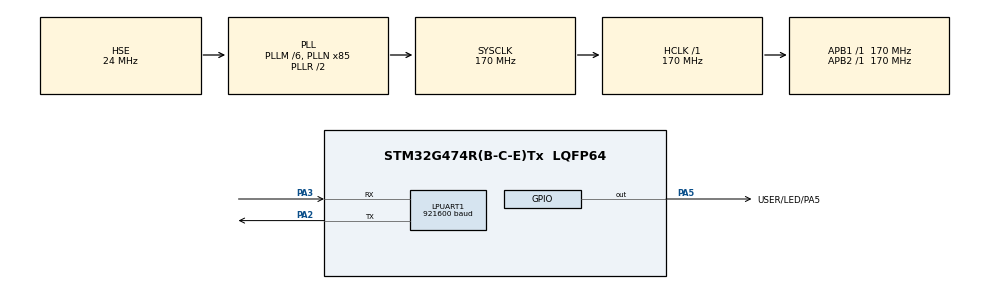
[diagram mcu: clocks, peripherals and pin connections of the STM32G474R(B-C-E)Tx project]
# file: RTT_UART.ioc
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LPUART1.BaudRate=921600
LPUART1.RXFIFOThreshold=UART_RXFIFO_THRESHOLD_3_4
LPUART1.TXFIFOThreshold=UART_TXFIFO_THRESHOLD_3_4
Mcu.Family=STM32G4
Mcu.Name=STM32G474R(B-C-E)Tx
Mcu.Package=LQFP64
NVIC.LPUART1_IRQn=true\:0\:0\:false\:false\:true\:true\:true
NVIC.PriorityGroup=NVIC_PRIORITYGROUP_4
PA2.Mode=Asynchronous
PA2.Signal=LPUART1_TX
PA3.Mode=Asynchronous
PA3.Signal=LPUART1_RX
PA5.GPIO_Label=USER/LED/PA5
PA5.Signal=GPIO_Output
PC14-OSC32_IN.Mode=LSE-External-Oscillator
PC14-OSC32_IN.Signal=RCC_OSC32_IN
PC15-OSC32_OUT.Mode=LSE-External-Oscillator
PC15-OSC32_OUT.Signal=RCC_OSC32_OUT
PF0-OSC_IN.Mode=HSE-External-Oscillator
PF0-OSC_IN.Signal=RCC_OSC_IN
PF1-OSC_OUT.Mode=HSE-External-Oscillator
PF1-OSC_OUT.Signal=RCC_OSC_OUT
ProjectManager.HeapSize=0x200
ProjectManager.StackSize=0x400
ProjectManager.TargetToolchain=MDK-ARM V5.27
RCC.ADC12Freq_Value=170000000
RCC.ADC345Freq_Value=170000000
RCC.AHBFreq_Value=170000000
RCC.APB1Freq_Value=170000000
RCC.APB1TimFreq_Value=170000000
RCC.APB2Freq_Value=170000000
RCC.APB2TimFreq_Value=170000000
RCC.CortexFreq_Value=170000000
RCC.EXTERNAL_CLOCK_VALUE=12288000
RCC.HCLKFreq_Value=170000000
RCC.HSE_VALUE=24000000
RCC.HSI48_VALUE=48000000
RCC.HSI_VALUE=16000000
RCC.PLLM=RCC_PLLM_DIV6
RCC.PLLN=85
RCC.PLLSourceVirtual=RCC_PLLSOURCE_HSE
RCC.SYSCLKFreq_VALUE=170000000
RCC.SYSCLKSource=RCC_SYSCLKSOURCE_PLLCLK
RCC.USBFreq_Value=170000000
RCC.VCOOutputFreq_Value=340000000
RealThread.RT-Thread.3.1.3.RTAaThreadCcRTOSJjkernel=true
RealThread.RT-Thread.3.1.3.RTAaThreadCcRTOSJjshell=true
VP_RealThread.RT-Thread_VS_RTOSJjRTAaThread_3.1.3.Mode=RTOSJjRTAaThread
VP_SYS_VS_DBSignals.Mode=DisableDeadBatterySignals
board=custom

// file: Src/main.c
/* USER CODE BEGIN Header */
/**
  ******************************************************************************
  * @file           : main.c
  * @brief          : Main program body
  ******************************************************************************
  * @attention
  *
  * <h2><center>&copy; Copyright (c) 2020 STMicroelectronics.
  * All rights reserved.</center></h2>
  *
  * This software component is licensed by ST under Ultimate Liberty license
  * SLA0044, the "License"; You may not use this file except in compliance with
  * the License. You may obtain a copy of the License at:
  *                             www.st.com/SLA0044
  *
  ******************************************************************************
  */
/* USER CODE END Header */

#include "main.h"
#include "usart.h"
#include "gpio.h"
//#include <stdio.h>
/* USER CODE BEGIN Includes */
#include <rtthread.h>
/* USER CODE END Includes */

/* USER CODE BEGIN PTD */
static struct rt_thread led_thread;
static char led_thread_stack[256];

/* USER CODE END PTD */

void SystemClock_Config(void);

/* USER CODE BEGIN 0 */
//编写线程入口函数
static void led_thread_entry(void *parameter)
{
	char sprintf_buf[128];
	float test_data = 1000.66666666f;
	while(1)
	{

		HAL_GPIO_WritePin(USER_LED_PA5_GPIO_Port,USER_LED_PA5_Pin, GPIO_PIN_SET);
		rt_thread_mdelay(500);
		HAL_GPIO_WritePin(USER_LED_PA5_GPIO_Port,USER_LED_PA5_Pin, GPIO_PIN_RESET);
		rt_thread_mdelay(500);
		snprintf(sprintf_buf, "%f\n", test_data);
		rt_kprintf(sprintf_buf);
		//rt_kprintf("%f\r\n",test_data);
		//rt_kprintf("i am fine .\r\n");
		//test_data += test_data;
	}
}

#if 0
int fputc(int ch, FILE *f)
{
	HAL_UART_Transmit(&hlpuart1, (uint8_t *)&ch, 1, 1);
	while(!__HAL_UART_GET_FLAG(&hlpuart1,UART_FLAG_TXE));
	return ch;
}
#endif

/* USER CODE END 0 */

int main(void)
{

  /* MCU Configuration--------------------------------------------------------*/

  /* Reset of all peripherals, Initializes the Flash interface and the Systick. */
  HAL_Init();

  /* Configure the system clock */
  SystemClock_Config();

  /* Initialize all configured peripherals */
  MX_GPIO_Init();
  MX_LPUART1_UART_Init();
  /* USER CODE BEGIN 2 */
	rt_err_t rst;
	rst = rt_thread_init(&led_thread,
						"ledshine",
						led_thread_entry,
						RT_NULL,
						&led_thread_stack[0],
						sizeof(led_thread_stack),
						RT_THREAD_PRIORITY_MAX-2,
					20);
	if(rst == RT_EOK)
	{
		rt_thread_startup(&led_thread);
	}

  /* USER CODE END 2 */

  /* Infinite loop */
  /* USER CODE BEGIN WHILE */

  /* USER CODE END 3 */
}

void SystemClock_Config(void)
{
  RCC_OscInitTypeDef RCC_OscInitStruct = {0};
  RCC_ClkInitTypeDef RCC_ClkInitStruct = {0};
  RCC_PeriphCLKInitTypeDef PeriphClkInit = {0};

  /** Configure the main internal regulator output voltage
  */
  HAL_PWREx_ControlVoltageScaling(PWR_REGULATOR_VOLTAGE_SCALE1_BOOST);
  /** Initializes the CPU, AHB and APB busses clocks
  */
  RCC_OscInitStruct.OscillatorType = RCC_OSCILLATORTYPE_HSE;
  RCC_OscInitStruct.HSEState = RCC_HSE_ON;
  RCC_OscInitStruct.PLL.PLLState = RCC_PLL_ON;
  RCC_OscInitStruct.PLL.PLLSource = RCC_PLLSOURCE_HSE;
  RCC_OscInitStruct.PLL.PLLM = RCC_PLLM_DIV6;
  RCC_OscInitStruct.PLL.PLLN = 85;
  RCC_OscInitStruct.PLL.PLLP = RCC_PLLP_DIV2;
  RCC_OscInitStruct.PLL.PLLQ = RCC_PLLQ_DIV2;
  RCC_OscInitStruct.PLL.PLLR = RCC_PLLR_DIV2;
  if (HAL_RCC_OscConfig(&RCC_OscInitStruct) != HAL_OK)
  {
    Error_Handler();
  }
  /** Initializes the CPU, AHB and APB busses clocks
  */
  RCC_ClkInitStruct.ClockType = RCC_CLOCKTYPE_HCLK|RCC_CLOCKTYPE_SYSCLK
                              |RCC_CLOCKTYPE_PCLK1|RCC_CLOCKTYPE_PCLK2;
  RCC_ClkInitStruct.SYSCLKSource = RCC_SYSCLKSOURCE_PLLCLK;
  RCC_ClkInitStruct.AHBCLKDivider = RCC_SYSCLK_DIV1;
  RCC_ClkInitStruct.APB1CLKDivider = RCC_HCLK_DIV1;
  RCC_ClkInitStruct.APB2CLKDivider = RCC_HCLK_DIV1;

  if (HAL_RCC_ClockConfig(&RCC_ClkInitStruct, FLASH_LATENCY_8) != HAL_OK)
  {
    Error_Handler();
  }
  /** Initializes the peripherals clocks
  */
  PeriphClkInit.PeriphClockSelection = RCC_PERIPHCLK_LPUART1;
  PeriphClkInit.Lpuart1ClockSelection = RCC_LPUART1CLKSOURCE_PCLK1;
  if (HAL_RCCEx_PeriphCLKConfig(&PeriphClkInit) != HAL_OK)
  {
    Error_Handler();
  }
}

void Error_Handler(void)
{
}

/************************ (C) COPYRIGHT STMicroelectronics *****END OF FILE****/
